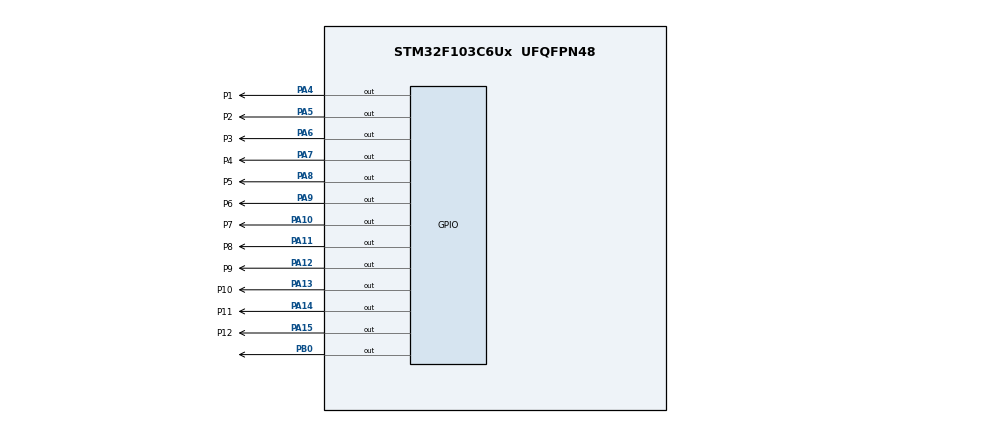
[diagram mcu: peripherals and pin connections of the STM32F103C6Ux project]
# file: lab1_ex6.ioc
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Mcu.Family=STM32F1
Mcu.Name=STM32F103C6Ux
Mcu.Package=UFQFPN48
NVIC.PriorityGroup=NVIC_PRIORITYGROUP_4
PA10.GPIO_Label=P7
PA10.Signal=GPIO_Output
PA11.GPIO_Label=P8
PA11.Signal=GPIO_Output
PA12.GPIO_Label=P9
PA12.Signal=GPIO_Output
PA13.GPIO_Label=P10
PA13.Signal=GPIO_Output
PA14.GPIO_Label=P11
PA14.Signal=GPIO_Output
PA15.GPIO_Label=P12
PA15.Signal=GPIO_Output
PA4.GPIO_Label=P1
PA4.Signal=GPIO_Output
PA5.GPIO_Label=P2
PA5.Signal=GPIO_Output
PA6.GPIO_Label=P3
PA6.Signal=GPIO_Output
PA7.GPIO_Label=P4
PA7.Signal=GPIO_Output
PA8.GPIO_Label=P5
PA8.Signal=GPIO_Output
PA9.GPIO_Label=P6
PA9.Signal=GPIO_Output
PB0.Signal=GPIO_Output
ProjectManager.HeapSize=0x200
ProjectManager.StackSize=0x400
ProjectManager.TargetToolchain=STM32CubeIDE
RCC.APB1Freq_Value=8000000
RCC.APB2Freq_Value=8000000
VP_SYS_VS_ND.Mode=No_Debug
board=custom

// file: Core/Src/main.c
/* USER CODE BEGIN Header */
/**
  ******************************************************************************
  * @file           : main.c
  * @brief          : Main program body
  ******************************************************************************
  * @attention
  *
  * <h2><center>&copy; Copyright (c) 2022 STMicroelectronics.
  * All rights reserved.</center></h2>
  *
  * This software component is licensed by ST under BSD 3-Clause license,
  * the "License"; You may not use this file except in compliance with the
  * License. You may obtain a copy of the License at:
  *                        opensource.org/licenses/BSD-3-Clause
  *
  ******************************************************************************
  */
/* USER CODE END Header */
#include "main.h"

void SystemClock_Config(void);
static void MX_GPIO_Init(void);

int main(void)
{

  /* MCU Configuration--------------------------------------------------------*/

  /* Reset of all peripherals, Initializes the Flash interface and the Systick. */
  HAL_Init();

  /* Configure the system clock */
  SystemClock_Config();

  /* Initialize all configured peripherals */
  MX_GPIO_Init();

  /* Infinite loop */
  /* USER CODE BEGIN WHILE */
  uint8_t i = 1;
  uint8_t j = 6;
  uint8_t k = 3;
  uint8_t h = 0;
  uint8_t t = 0;
   while (1)
   {
    /* USER CODE END WHILE */
	   for(int i = 0; i<12;i++ )
	     {
	   	  setNumonClock(i);
	   	  HAL_Delay(500);
	   	  }
	   ClearAllClock();
   /* USER CODE END 3 */
 }

}
void ClearAllClock(){
  	  HAL_GPIO_WritePin ( P1_GPIO_Port , P1_Pin ,GPIO_PIN_RESET );
  	  HAL_GPIO_WritePin ( P2_GPIO_Port , P2_Pin ,GPIO_PIN_RESET );
  	  HAL_GPIO_WritePin ( P3_GPIO_Port , P3_Pin ,GPIO_PIN_RESET );
  	  HAL_GPIO_WritePin ( P4_GPIO_Port , P4_Pin ,GPIO_PIN_RESET );
  	  HAL_GPIO_WritePin ( P5_GPIO_Port , P5_Pin ,GPIO_PIN_RESET );
  	  HAL_GPIO_WritePin ( P6_GPIO_Port , P6_Pin ,GPIO_PIN_RESET );
  	  HAL_GPIO_WritePin ( P7_GPIO_Port , P7_Pin ,GPIO_PIN_RESET );
  	  HAL_GPIO_WritePin ( P8_GPIO_Port , P8_Pin ,GPIO_PIN_RESET );
  	  HAL_GPIO_WritePin ( P9_GPIO_Port , P9_Pin ,GPIO_PIN_RESET );
  	  HAL_GPIO_WritePin ( P10_GPIO_Port , P10_Pin ,GPIO_PIN_RESET );
  	  HAL_GPIO_WritePin ( P11_GPIO_Port , P11_Pin ,GPIO_PIN_RESET );
  	  HAL_GPIO_WritePin ( P12_GPIO_Port , P12_Pin ,GPIO_PIN_RESET);
}
 void setNumonClock(int a)
   {
	 switch(a){
	 case 0:
 		  	  HAL_GPIO_WritePin ( P12_GPIO_Port , P12_Pin ,GPIO_PIN_SET);
 		  	  break;
	 case 1:

 	  	  HAL_GPIO_WritePin ( P1_GPIO_Port , P1_Pin ,GPIO_PIN_SET );
 	  	  /*HAL_GPIO_WritePin ( P2_GPIO_Port , P2_Pin ,GPIO_PIN_RESET );
 	  	  HAL_GPIO_WritePin ( P3_GPIO_Port , P3_Pin ,GPIO_PIN_RESET);
 	  	  HAL_GPIO_WritePin ( P4_GPIO_Port , P4_Pin ,GPIO_PIN_RESET );
 	  	  HAL_GPIO_WritePin ( P5_GPIO_Port , P5_Pin ,GPIO_PIN_RESET );
 	  	  HAL_GPIO_WritePin ( P6_GPIO_Port , P6_Pin ,GPIO_PIN_RESET );
 	  	  HAL_GPIO_WritePin ( P7_GPIO_Port , P7_Pin ,GPIO_PIN_RESET );
 	  	  HAL_GPIO_WritePin ( P8_GPIO_Port , P8_Pin ,GPIO_PIN_RESET);
 	  	  HAL_GPIO_WritePin ( P9_GPIO_Port , P9_Pin ,GPIO_PIN_RESET );
 	  	  HAL_GPIO_WritePin ( P10_GPIO_Port , P10_Pin ,GPIO_PIN_RESET );
 	  	  HAL_GPIO_WritePin ( P11_GPIO_Port , P11_Pin ,GPIO_PIN_RESET );
 	  	  HAL_GPIO_WritePin ( P12_GPIO_Port , P12_Pin ,GPIO_PIN_RESET );*/

 	break;
	 case 2:

 	  	  //HAL_GPIO_WritePin ( P1_GPIO_Port , P1_Pin ,GPIO_PIN_RESET );
 	  	  HAL_GPIO_WritePin ( P2_GPIO_Port , P2_Pin ,GPIO_PIN_SET );
 	  	  /*HAL_GPIO_WritePin ( P3_GPIO_Port , P3_Pin ,GPIO_PIN_RESET );
 	  	  HAL_GPIO_WritePin ( P4_GPIO_Port , P4_Pin ,GPIO_PIN_RESET );
 	  	  HAL_GPIO_WritePin ( P5_GPIO_Port , P5_Pin ,GPIO_PIN_RESET );
 	  	  HAL_GPIO_WritePin ( P6_GPIO_Port , P6_Pin ,GPIO_PIN_RESET);
 	  	  HAL_GPIO_WritePin ( P7_GPIO_Port , P7_Pin ,GPIO_PIN_RESET );
 	  	  HAL_GPIO_WritePin ( P8_GPIO_Port , P8_Pin ,GPIO_PIN_RESET );
 	  	  HAL_GPIO_WritePin ( P9_GPIO_Port , P9_Pin ,GPIO_PIN_RESET);
 	  	  HAL_GPIO_WritePin ( P10_GPIO_Port , P10_Pin ,GPIO_PIN_RESET );
 	  	  HAL_GPIO_WritePin ( P11_GPIO_Port , P11_Pin ,GPIO_PIN_RESET );
 	  	  HAL_GPIO_WritePin ( P12_GPIO_Port , P12_Pin ,GPIO_PIN_RESET );*/

 	break;
	 case 3:

 	  	  //HAL_GPIO_WritePin ( P1_GPIO_Port , P1_Pin ,GPIO_PIN_RESET );
 	  	  //HAL_GPIO_WritePin ( P2_GPIO_Port , P2_Pin ,GPIO_PIN_RESET );
 	  	  HAL_GPIO_WritePin ( P3_GPIO_Port , P3_Pin ,GPIO_PIN_SET );
 	  	  /*HAL_GPIO_WritePin ( P4_GPIO_Port , P4_Pin ,GPIO_PIN_RESET );
 	  	  HAL_GPIO_WritePin ( P5_GPIO_Port , P5_Pin ,GPIO_PIN_RESET );
 	  	  HAL_GPIO_WritePin ( P6_GPIO_Port , P6_Pin ,GPIO_PIN_RESET );
 	  	  HAL_GPIO_WritePin ( P7_GPIO_Port , P7_Pin ,GPIO_PIN_RESET );
 	  	  HAL_GPIO_WritePin ( P8_GPIO_Port , P8_Pin ,GPIO_PIN_RESET );
 	  	  HAL_GPIO_WritePin ( P9_GPIO_Port , P9_Pin ,GPIO_PIN_RESET );
 	  	  HAL_GPIO_WritePin ( P10_GPIO_Port , P10_Pin ,GPIO_PIN_RESET );
 	  	  HAL_GPIO_WritePin ( P11_GPIO_Port , P11_Pin ,GPIO_PIN_RESET );
 	  	  HAL_GPIO_WritePin ( P12_GPIO_Port , P12_Pin ,GPIO_PIN_RESET);*/

 	break;
	 case 4:

 	  	 /*HAL_GPIO_WritePin ( P1_GPIO_Port , P1_Pin ,GPIO_PIN_RESET );
 	  	 HAL_GPIO_WritePin ( P2_GPIO_Port , P2_Pin ,GPIO_PIN_RESET );
 	  	 HAL_GPIO_WritePin ( P3_GPIO_Port , P3_Pin ,GPIO_PIN_RESET );*/
 		 HAL_GPIO_WritePin ( P4_GPIO_Port , P4_Pin ,GPIO_PIN_SET );
 	  	 /*HAL_GPIO_WritePin ( P5_GPIO_Port , P5_Pin ,GPIO_PIN_RESET );
 	  	 HAL_GPIO_WritePin ( P6_GPIO_Port , P6_Pin ,GPIO_PIN_RESET );
 	  	 HAL_GPIO_WritePin ( P7_GPIO_Port , P7_Pin ,GPIO_PIN_RESET );
 	  	 HAL_GPIO_WritePin ( P8_GPIO_Port , P8_Pin ,GPIO_PIN_RESET );
 	  	 HAL_GPIO_WritePin ( P9_GPIO_Port , P9_Pin ,GPIO_PIN_RESET );
 	  	 HAL_GPIO_WritePin ( P10_GPIO_Port , P10_Pin ,GPIO_PIN_RESET );
 	  	 HAL_GPIO_WritePin ( P11_GPIO_Port , P11_Pin ,GPIO_PIN_RESET );
 	  	 HAL_GPIO_WritePin ( P12_GPIO_Port , P12_Pin ,GPIO_PIN_RESET);*/

 	break;
	 case 5:

 	  	  //HAL_GPIO_WritePin ( P1_GPIO_Port , P1_Pin ,GPIO_PIN_RESET );
 	  	  //HAL_GPIO_WritePin ( P2_GPIO_Port , P2_Pin ,GPIO_PIN_RESET );
 	  	  //HAL_GPIO_WritePin ( P3_GPIO_Port , P3_Pin ,GPIO_PIN_RESET );
 	  	  //HAL_GPIO_WritePin ( P4_GPIO_Port , P4_Pin ,GPIO_PIN_RESET );
 	  	   HAL_GPIO_WritePin ( P5_GPIO_Port , P5_Pin ,GPIO_PIN_SET );
 	  	  //HAL_GPIO_WritePin ( P6_GPIO_Port , P6_Pin ,GPIO_PIN_RESET );
 	  	  //HAL_GPIO_WritePin ( P7_GPIO_Port , P7_Pin ,GPIO_PIN_RESET );
 	  	  //HAL_GPIO_WritePin ( P8_GPIO_Port , P8_Pin ,GPIO_PIN_RESET );
 	  	  //HAL_GPIO_WritePin ( P9_GPIO_Port , P9_Pin ,GPIO_PIN_RESET );
 	  	  //HAL_GPIO_WritePin ( P10_GPIO_Port , P10_Pin ,GPIO_PIN_RESET );
 	  	  //HAL_GPIO_WritePin ( P11_GPIO_Port , P11_Pin ,GPIO_PIN_RESET );
 	  	  //HAL_GPIO_WritePin ( P12_GPIO_Port , P12_Pin ,GPIO_PIN_RESET);

 	break;
	 case 6:

 	  	  //HAL_GPIO_WritePin ( P1_GPIO_Port , P1_Pin ,GPIO_PIN_RESET );
 	  	  //HAL_GPIO_WritePin ( P2_GPIO_Port , P2_Pin ,GPIO_PIN_RESET );
 	  	  //HAL_GPIO_WritePin ( P3_GPIO_Port , P3_Pin ,GPIO_PIN_RESET );
 	  	  //HAL_GPIO_WritePin ( P4_GPIO_Port , P4_Pin ,GPIO_PIN_RESET );
 	  	  //HAL_GPIO_WritePin ( P5_GPIO_Port , P5_Pin ,GPIO_PIN_RESET );
 	  	  HAL_GPIO_WritePin ( P6_GPIO_Port , P6_Pin ,GPIO_PIN_SET );
 	  	  //HAL_GPIO_WritePin ( P7_GPIO_Port , P7_Pin ,GPIO_PIN_RESET );
 	  	  //HAL_GPIO_WritePin ( P8_GPIO_Port , P8_Pin ,GPIO_PIN_RESET );
 	  	  //HAL_GPIO_WritePin ( P9_GPIO_Port , P9_Pin ,GPIO_PIN_RESET );
 	  	  //HAL_GPIO_WritePin ( P10_GPIO_Port , P10_Pin ,GPIO_PIN_RESET );
 	  	  //HAL_GPIO_WritePin ( P11_GPIO_Port , P11_Pin ,GPIO_PIN_RESET );
 	  	  //HAL_GPIO_WritePin ( P12_GPIO_Port , P12_Pin ,GPIO_PIN_RESET);

 	break;
	 case 7:

 	  	  //HAL_GPIO_WritePin ( P1_GPIO_Port , P1_Pin ,GPIO_PIN_RESET );
 	  	  //HAL_GPIO_WritePin ( P2_GPIO_Port , P2_Pin ,GPIO_PIN_RESET );
 	  	  //HAL_GPIO_WritePin ( P3_GPIO_Port , P3_Pin ,GPIO_PIN_RESET );
 	  	  //HAL_GPIO_WritePin ( P4_GPIO_Port , P4_Pin ,GPIO_PIN_RESET );
 	  	  //HAL_GPIO_WritePin ( P5_GPIO_Port , P5_Pin ,GPIO_PIN_RESET );
 	  	 // HAL_GPIO_WritePin ( P6_GPIO_Port , P6_Pin ,GPIO_PIN_RESET );
 	  	  HAL_GPIO_WritePin ( P7_GPIO_Port , P7_Pin ,GPIO_PIN_SET );
 	  	 // HAL_GPIO_WritePin ( P8_GPIO_Port , P8_Pin ,GPIO_PIN_RESET );
 	  	 // HAL_GPIO_WritePin ( P9_GPIO_Port , P9_Pin ,GPIO_PIN_RESET );
 	  	//  HAL_GPIO_WritePin ( P10_GPIO_Port , P10_Pin ,GPIO_PIN_RESET );
 	  	//  HAL_GPIO_WritePin ( P11_GPIO_Port , P11_Pin ,GPIO_PIN_RESET );
 	  	//  HAL_GPIO_WritePin ( P12_GPIO_Port , P12_Pin ,GPIO_PIN_RESET);

 	break;
	 case 8:

 	 	  //HAL_GPIO_WritePin ( P1_GPIO_Port , P1_Pin ,GPIO_PIN_RESET );
 	  	  //HAL_GPIO_WritePin ( P2_GPIO_Port , P2_Pin ,GPIO_PIN_RESET );
 	  	  //HAL_GPIO_WritePin ( P3_GPIO_Port , P3_Pin ,GPIO_PIN_RESET );
 	  	  //HAL_GPIO_WritePin ( P4_GPIO_Port , P4_Pin ,GPIO_PIN_RESET );
 	  	  //HAL_GPIO_WritePin ( P5_GPIO_Port , P5_Pin ,GPIO_PIN_RESET );
 	  	  //HAL_GPIO_WritePin ( P6_GPIO_Port , P6_Pin ,GPIO_PIN_RESET );
 	  	  //HAL_GPIO_WritePin ( P7_GPIO_Port , P7_Pin ,GPIO_PIN_RESET );
 	  	  HAL_GPIO_WritePin ( P8_GPIO_Port , P8_Pin ,GPIO_PIN_SET );
 	  	  //HAL_GPIO_WritePin ( P9_GPIO_Port , P9_Pin ,GPIO_PIN_RESET );
 	  	  //HAL_GPIO_WritePin ( P10_GPIO_Port , P10_Pin ,GPIO_PIN_RESET );
 	  	  //HAL_GPIO_WritePin ( P11_GPIO_Port , P11_Pin ,GPIO_PIN_RESET );
 	  	  //HAL_GPIO_WritePin ( P12_GPIO_Port , P12_Pin ,GPIO_PIN_RESET);

 	break;
	 case 9:

 	  	  //HAL_GPIO_WritePin ( P1_GPIO_Port , P1_Pin ,GPIO_PIN_RESET );
 	  	  //HAL_GPIO_WritePin ( P2_GPIO_Port , P2_Pin ,GPIO_PIN_RESET );
 	  	  //HAL_GPIO_WritePin ( P3_GPIO_Port , P3_Pin ,GPIO_PIN_RESET );
 	  	  //HAL_GPIO_WritePin ( P4_GPIO_Port , P4_Pin ,GPIO_PIN_RESET );
 	  	  //HAL_GPIO_WritePin ( P5_GPIO_Port , P5_Pin ,GPIO_PIN_RESET );
 	  	  //HAL_GPIO_WritePin ( P6_GPIO_Port , P6_Pin ,GPIO_PIN_RESET );
 	  	  //HAL_GPIO_WritePin ( P7_GPIO_Port , P7_Pin ,GPIO_PIN_RESET );
 	  	  //HAL_GPIO_WritePin ( P8_GPIO_Port , P8_Pin ,GPIO_PIN_RESET );
 	  	  HAL_GPIO_WritePin ( P9_GPIO_Port , P9_Pin ,GPIO_PIN_SET );
 	  	  //HAL_GPIO_WritePin ( P10_GPIO_Port , P10_Pin ,GPIO_PIN_RESET );
 	  	  //HAL_GPIO_WritePin ( P11_GPIO_Port , P11_Pin ,GPIO_PIN_RESET );
 	  	  //HAL_GPIO_WritePin ( P12_GPIO_Port , P12_Pin ,GPIO_PIN_RESET);

 	break;
	 case 10:

 	  	  //HAL_GPIO_WritePin ( P1_GPIO_Port , P1_Pin ,GPIO_PIN_RESET );
 	  	  //HAL_GPIO_WritePin ( P2_GPIO_Port , P2_Pin ,GPIO_PIN_RESET );
 	  	  //HAL_GPIO_WritePin ( P3_GPIO_Port , P3_Pin ,GPIO_PIN_RESET );
 	  	  //HAL_GPIO_WritePin ( P4_GPIO_Port , P4_Pin ,GPIO_PIN_RESET );
 	  	  //HAL_GPIO_WritePin ( P5_GPIO_Port , P5_Pin ,GPIO_PIN_RESET );
 	  	  //HAL_GPIO_WritePin ( P6_GPIO_Port , P6_Pin ,GPIO_PIN_RESET );
 	  	  //HAL_GPIO_WritePin ( P7_GPIO_Port , P7_Pin ,GPIO_PIN_RESET );
 	  	  //HAL_GPIO_WritePin ( P8_GPIO_Port , P8_Pin ,GPIO_PIN_RESET );
 	  	  //HAL_GPIO_WritePin ( P9_GPIO_Port , P9_Pin ,GPIO_PIN_RESET );
 	  	  HAL_GPIO_WritePin ( P10_GPIO_Port , P10_Pin ,GPIO_PIN_SET );
 	  	  //HAL_GPIO_WritePin ( P11_GPIO_Port , P11_Pin ,GPIO_PIN_RESET );
 	  	  //HAL_GPIO_WritePin ( P12_GPIO_Port , P12_Pin ,GPIO_PIN_RESET);

 		break;
	 case 11:

 	  	  //HAL_GPIO_WritePin ( P1_GPIO_Port , P1_Pin ,GPIO_PIN_RESET );
 	  	  //HAL_GPIO_WritePin ( P2_GPIO_Port , P2_Pin ,GPIO_PIN_RESET );
 	  	  //HAL_GPIO_WritePin ( P3_GPIO_Port , P3_Pin ,GPIO_PIN_RESET );
 	  	  //HAL_GPIO_WritePin ( P4_GPIO_Port , P4_Pin ,GPIO_PIN_RESET );
 	  	  //HAL_GPIO_WritePin ( P5_GPIO_Port , P5_Pin ,GPIO_PIN_RESET );
 	  	  //HAL_GPIO_WritePin ( P6_GPIO_Port , P6_Pin ,GPIO_PIN_RESET );
 	  	  //HAL_GPIO_WritePin ( P7_GPIO_Port , P7_Pin ,GPIO_PIN_RESET );
 	  	  //HAL_GPIO_WritePin ( P8_GPIO_Port , P8_Pin ,GPIO_PIN_RESET );
 	  	  //HAL_GPIO_WritePin ( P9_GPIO_Port , P9_Pin ,GPIO_PIN_RESET );
 	  	  //HAL_GPIO_WritePin ( P10_GPIO_Port , P10_Pin ,GPIO_PIN_RESET );
 	  	  HAL_GPIO_WritePin ( P11_GPIO_Port , P11_Pin ,GPIO_PIN_SET );
 	  	  //HAL_GPIO_WritePin ( P12_GPIO_Port , P12_Pin ,GPIO_PIN_RESET);

 		break;
	 default:
		 break;
	 }
   }
 void setNumoffClock(int a)
    {
  	/*if(a==0)
  	{
  		  	  HAL_GPIO_WritePin ( P1_GPIO_Port , P1_Pin ,GPIO_PIN_RESET );
  		  	  HAL_GPIO_WritePin ( P2_GPIO_Port , P2_Pin ,GPIO_PIN_RESET );
  		  	  HAL_GPIO_WritePin ( P3_GPIO_Port , P3_Pin ,GPIO_PIN_RESET );
  		  	  HAL_GPIO_WritePin ( P4_GPIO_Port , P4_Pin ,GPIO_PIN_RESET );
  		  	  HAL_GPIO_WritePin ( P5_GPIO_Port , P5_Pin ,GPIO_PIN_RESET );
  		  	  HAL_GPIO_WritePin ( P6_GPIO_Port , P6_Pin ,GPIO_PIN_RESET );
  		  	  HAL_GPIO_WritePin ( P7_GPIO_Port , P7_Pin ,GPIO_PIN_RESET );
  		  	  HAL_GPIO_WritePin ( P8_GPIO_Port , P8_Pin ,GPIO_PIN_RESET );
  		  	  HAL_GPIO_WritePin ( P9_GPIO_Port , P9_Pin ,GPIO_PIN_RESET );
  		  	  HAL_GPIO_WritePin ( P10_GPIO_Port , P10_Pin ,GPIO_PIN_RESET );
  		  	  HAL_GPIO_WritePin ( P11_GPIO_Port , P11_Pin ,GPIO_PIN_RESET );
  		  	  HAL_GPIO_WritePin ( P12_GPIO_Port , P12_Pin ,GPIO_PIN_RESET);
  	}*/
	 switch(a){
	 case 0:
 		  	  HAL_GPIO_WritePin ( P12_GPIO_Port , P12_Pin ,GPIO_PIN_RESET);
 		  	  break;
	 case 1:

 	  	  HAL_GPIO_WritePin ( P1_GPIO_Port , P1_Pin ,GPIO_PIN_RESET );
 	  	  /*HAL_GPIO_WritePin ( P2_GPIO_Port , P2_Pin ,GPIO_PIN_RESET );
 	  	  HAL_GPIO_WritePin ( P3_GPIO_Port , P3_Pin ,GPIO_PIN_RESET);
 	  	  HAL_GPIO_WritePin ( P4_GPIO_Port , P4_Pin ,GPIO_PIN_RESET );
 	  	  HAL_GPIO_WritePin ( P5_GPIO_Port , P5_Pin ,GPIO_PIN_RESET );
 	  	  HAL_GPIO_WritePin ( P6_GPIO_Port , P6_Pin ,GPIO_PIN_RESET );
 	  	  HAL_GPIO_WritePin ( P7_GPIO_Port , P7_Pin ,GPIO_PIN_RESET );
 	  	  HAL_GPIO_WritePin ( P8_GPIO_Port , P8_Pin ,GPIO_PIN_RESET);
 	  	  HAL_GPIO_WritePin ( P9_GPIO_Port , P9_Pin ,GPIO_PIN_RESET );
 	  	  HAL_GPIO_WritePin ( P10_GPIO_Port , P10_Pin ,GPIO_PIN_RESET );
 	  	  HAL_GPIO_WritePin ( P11_GPIO_Port , P11_Pin ,GPIO_PIN_RESET );
 	  	  HAL_GPIO_WritePin ( P12_GPIO_Port , P12_Pin ,GPIO_PIN_RESET );*/

 	break;
	 case 2:

 	  	  //HAL_GPIO_WritePin ( P1_GPIO_Port , P1_Pin ,GPIO_PIN_RESET );
 	  	  HAL_GPIO_WritePin ( P2_GPIO_Port , P2_Pin ,GPIO_PIN_RESET );
 	  	  /*HAL_GPIO_WritePin ( P3_GPIO_Port , P3_Pin ,GPIO_PIN_RESET );
 	  	  HAL_GPIO_WritePin ( P4_GPIO_Port , P4_Pin ,GPIO_PIN_RESET );
 	  	  HAL_GPIO_WritePin ( P5_GPIO_Port , P5_Pin ,GPIO_PIN_RESET );
 	  	  HAL_GPIO_WritePin ( P6_GPIO_Port , P6_Pin ,GPIO_PIN_RESET);
 	  	  HAL_GPIO_WritePin ( P7_GPIO_Port , P7_Pin ,GPIO_PIN_RESET );
 	  	  HAL_GPIO_WritePin ( P8_GPIO_Port , P8_Pin ,GPIO_PIN_RESET );
 	  	  HAL_GPIO_WritePin ( P9_GPIO_Port , P9_Pin ,GPIO_PIN_RESET);
 	  	  HAL_GPIO_WritePin ( P10_GPIO_Port , P10_Pin ,GPIO_PIN_RESET );
 	  	  HAL_GPIO_WritePin ( P11_GPIO_Port , P11_Pin ,GPIO_PIN_RESET );
 	  	  HAL_GPIO_WritePin ( P12_GPIO_Port , P12_Pin ,GPIO_PIN_RESET );*/

 	break;
	 case 3:

 	  	  //HAL_GPIO_WritePin ( P1_GPIO_Port , P1_Pin ,GPIO_PIN_RESET );
 	  	  //HAL_GPIO_WritePin ( P2_GPIO_Port , P2_Pin ,GPIO_PIN_RESET );
 	  	  HAL_GPIO_WritePin ( P3_GPIO_Port , P3_Pin ,GPIO_PIN_RESET );
 	  	  /*HAL_GPIO_WritePin ( P4_GPIO_Port , P4_Pin ,GPIO_PIN_RESET );
 	  	  HAL_GPIO_WritePin ( P5_GPIO_Port , P5_Pin ,GPIO_PIN_RESET );
 	  	  HAL_GPIO_WritePin ( P6_GPIO_Port , P6_Pin ,GPIO_PIN_RESET );
 	  	  HAL_GPIO_WritePin ( P7_GPIO_Port , P7_Pin ,GPIO_PIN_RESET );
 	  	  HAL_GPIO_WritePin ( P8_GPIO_Port , P8_Pin ,GPIO_PIN_RESET );
 	  	  HAL_GPIO_WritePin ( P9_GPIO_Port , P9_Pin ,GPIO_PIN_RESET );
 	  	  HAL_GPIO_WritePin ( P10_GPIO_Port , P10_Pin ,GPIO_PIN_RESET );
 	  	  HAL_GPIO_WritePin ( P11_GPIO_Port , P11_Pin ,GPIO_PIN_RESET );
 	  	  HAL_GPIO_WritePin ( P12_GPIO_Port , P12_Pin ,GPIO_PIN_RESET);*/

 	break;
	 case 4:

 	  	 /*HAL_GPIO_WritePin ( P1_GPIO_Port , P1_Pin ,GPIO_PIN_RESET );
 	  	 HAL_GPIO_WritePin ( P2_GPIO_Port , P2_Pin ,GPIO_PIN_RESET );
 	  	 HAL_GPIO_WritePin ( P3_GPIO_Port , P3_Pin ,GPIO_PIN_RESET );*/
 		 HAL_GPIO_WritePin ( P4_GPIO_Port , P4_Pin ,GPIO_PIN_RESET );
 	  	 /*HAL_GPIO_WritePin ( P5_GPIO_Port , P5_Pin ,GPIO_PIN_RESET );
 	  	 HAL_GPIO_WritePin ( P6_GPIO_Port , P6_Pin ,GPIO_PIN_RESET );
 	  	 HAL_GPIO_WritePin ( P7_GPIO_Port , P7_Pin ,GPIO_PIN_RESET );
 	  	 HAL_GPIO_WritePin ( P8_GPIO_Port , P8_Pin ,GPIO_PIN_RESET );
 	  	 HAL_GPIO_WritePin ( P9_GPIO_Port , P9_Pin ,GPIO_PIN_RESET );
 	  	 HAL_GPIO_WritePin ( P10_GPIO_Port , P10_Pin ,GPIO_PIN_RESET );
 	  	 HAL_GPIO_WritePin ( P11_GPIO_Port , P11_Pin ,GPIO_PIN_RESET );
 	  	 HAL_GPIO_WritePin ( P12_GPIO_Port , P12_Pin ,GPIO_PIN_RESET);*/

 	break;
	 case 5:

 	  	  //HAL_GPIO_WritePin ( P1_GPIO_Port , P1_Pin ,GPIO_PIN_RESET );
 	  	  //HAL_GPIO_WritePin ( P2_GPIO_Port , P2_Pin ,GPIO_PIN_RESET );
 	  	  //HAL_GPIO_WritePin ( P3_GPIO_Port , P3_Pin ,GPIO_PIN_RESET );
 	  	  //HAL_GPIO_WritePin ( P4_GPIO_Port , P4_Pin ,GPIO_PIN_RESET );
 	  	   HAL_GPIO_WritePin ( P5_GPIO_Port , P5_Pin ,GPIO_PIN_RESET );
 	  	  //HAL_GPIO_WritePin ( P6_GPIO_Port , P6_Pin ,GPIO_PIN_RESET );
 	  	  //HAL_GPIO_WritePin ( P7_GPIO_Port , P7_Pin ,GPIO_PIN_RESET );
 	  	  //HAL_GPIO_WritePin ( P8_GPIO_Port , P8_Pin ,GPIO_PIN_RESET );
 	  	  //HAL_GPIO_WritePin ( P9_GPIO_Port , P9_Pin ,GPIO_PIN_RESET );
 	  	  //HAL_GPIO_WritePin ( P10_GPIO_Port , P10_Pin ,GPIO_PIN_RESET );
 	  	  //HAL_GPIO_WritePin ( P11_GPIO_Port , P11_Pin ,GPIO_PIN_RESET );
 	  	  //HAL_GPIO_WritePin ( P12_GPIO_Port , P12_Pin ,GPIO_PIN_RESET);

 	break;
	 case 6:

 	  	  //HAL_GPIO_WritePin ( P1_GPIO_Port , P1_Pin ,GPIO_PIN_RESET );
 	  	  //HAL_GPIO_WritePin ( P2_GPIO_Port , P2_Pin ,GPIO_PIN_RESET );
 	  	  //HAL_GPIO_WritePin ( P3_GPIO_Port , P3_Pin ,GPIO_PIN_RESET );
 	  	  //HAL_GPIO_WritePin ( P4_GPIO_Port , P4_Pin ,GPIO_PIN_RESET );
 	  	  //HAL_GPIO_WritePin ( P5_GPIO_Port , P5_Pin ,GPIO_PIN_RESET );
 	  	  HAL_GPIO_WritePin ( P6_GPIO_Port , P6_Pin ,GPIO_PIN_RESET );
 	  	  //HAL_GPIO_WritePin ( P7_GPIO_Port , P7_Pin ,GPIO_PIN_RESET );
 	  	  //HAL_GPIO_WritePin ( P8_GPIO_Port , P8_Pin ,GPIO_PIN_RESET );
 	  	  //HAL_GPIO_WritePin ( P9_GPIO_Port , P9_Pin ,GPIO_PIN_RESET );
 	  	  //HAL_GPIO_WritePin ( P10_GPIO_Port , P10_Pin ,GPIO_PIN_RESET );
 	  	  //HAL_GPIO_WritePin ( P11_GPIO_Port , P11_Pin ,GPIO_PIN_RESET );
 	  	  //HAL_GPIO_WritePin ( P12_GPIO_Port , P12_Pin ,GPIO_PIN_RESET);

 	break;
	 case 7:

 	  	  //HAL_GPIO_WritePin ( P1_GPIO_Port , P1_Pin ,GPIO_PIN_RESET );
 	  	  //HAL_GPIO_WritePin ( P2_GPIO_Port , P2_Pin ,GPIO_PIN_RESET );
 	  	  //HAL_GPIO_WritePin ( P3_GPIO_Port , P3_Pin ,GPIO_PIN_RESET );
 	  	  //HAL_GPIO_WritePin ( P4_GPIO_Port , P4_Pin ,GPIO_PIN_RESET );
 	  	  //HAL_GPIO_WritePin ( P5_GPIO_Port , P5_Pin ,GPIO_PIN_RESET );
 	  	 // HAL_GPIO_WritePin ( P6_GPIO_Port , P6_Pin ,GPIO_PIN_RESET );
 	  	  HAL_GPIO_WritePin ( P7_GPIO_Port , P7_Pin ,GPIO_PIN_RESET );
 	  	 // HAL_GPIO_WritePin ( P8_GPIO_Port , P8_Pin ,GPIO_PIN_RESET );
 	  	 // HAL_GPIO_WritePin ( P9_GPIO_Port , P9_Pin ,GPIO_PIN_RESET );
 	  	//  HAL_GPIO_WritePin ( P10_GPIO_Port , P10_Pin ,GPIO_PIN_RESET );
 	  	//  HAL_GPIO_WritePin ( P11_GPIO_Port , P11_Pin ,GPIO_PIN_RESET );
 	  	//  HAL_GPIO_WritePin ( P12_GPIO_Port , P12_Pin ,GPIO_PIN_RESET);

 	break;
	 case 8:

 	  	  //HAL_GPIO_WritePin ( P1_GPIO_Port , P1_Pin ,GPIO_PIN_RESET );
 	  	  //HAL_GPIO_WritePin ( P2_GPIO_Port , P2_Pin ,GPIO_PIN_RESET );
 	  	  //HAL_GPIO_WritePin ( P3_GPIO_Port , P3_Pin ,GPIO_PIN_RESET );
 	  	  //HAL_GPIO_WritePin ( P4_GPIO_Port , P4_Pin ,GPIO_PIN_RESET );
 	  	  //HAL_GPIO_WritePin ( P5_GPIO_Port , P5_Pin ,GPIO_PIN_RESET );
 	  	  //HAL_GPIO_WritePin ( P6_GPIO_Port , P6_Pin ,GPIO_PIN_RESET );
 	  	  //HAL_GPIO_WritePin ( P7_GPIO_Port , P7_Pin ,GPIO_PIN_RESET );
 	  	  HAL_GPIO_WritePin ( P8_GPIO_Port , P8_Pin ,GPIO_PIN_RESET );
 	  	  //HAL_GPIO_WritePin ( P9_GPIO_Port , P9_Pin ,GPIO_PIN_RESET );
 	  	  //HAL_GPIO_WritePin ( P10_GPIO_Port , P10_Pin ,GPIO_PIN_RESET );
 	  	  //HAL_GPIO_WritePin ( P11_GPIO_Port , P11_Pin ,GPIO_PIN_RESET );
 	  	  //HAL_GPIO_WritePin ( P12_GPIO_Port , P12_Pin ,GPIO_PIN_RESET);

 	break;
	 case 9:

 	  	  //HAL_GPIO_WritePin ( P1_GPIO_Port , P1_Pin ,GPIO_PIN_RESET );
 	  	  //HAL_GPIO_WritePin ( P2_GPIO_Port , P2_Pin ,GPIO_PIN_RESET );
 	  	  //HAL_GPIO_WritePin ( P3_GPIO_Port , P3_Pin ,GPIO_PIN_RESET );
 	  	  //HAL_GPIO_WritePin ( P4_GPIO_Port , P4_Pin ,GPIO_PIN_RESET );
 	  	  //HAL_GPIO_WritePin ( P5_GPIO_Port , P5_Pin ,GPIO_PIN_RESET );
 	  	  //HAL_GPIO_WritePin ( P6_GPIO_Port , P6_Pin ,GPIO_PIN_RESET );
 	  	  //HAL_GPIO_WritePin ( P7_GPIO_Port , P7_Pin ,GPIO_PIN_RESET );
 	  	  //HAL_GPIO_WritePin ( P8_GPIO_Port , P8_Pin ,GPIO_PIN_RESET );
 	  	  HAL_GPIO_WritePin ( P9_GPIO_Port , P9_Pin ,GPIO_PIN_RESET );
 	  	  //HAL_GPIO_WritePin ( P10_GPIO_Port , P10_Pin ,GPIO_PIN_RESET );
 	  	  //HAL_GPIO_WritePin ( P11_GPIO_Port , P11_Pin ,GPIO_PIN_RESET );
 	  	  //HAL_GPIO_WritePin ( P12_GPIO_Port , P12_Pin ,GPIO_PIN_RESET);

 	break;
	 case 10:

 	  	  //HAL_GPIO_WritePin ( P1_GPIO_Port , P1_Pin ,GPIO_PIN_RESET );
 	  	  //HAL_GPIO_WritePin ( P2_GPIO_Port , P2_Pin ,GPIO_PIN_RESET );
 	  	  //HAL_GPIO_WritePin ( P3_GPIO_Port , P3_Pin ,GPIO_PIN_RESET );
 	  	  //HAL_GPIO_WritePin ( P4_GPIO_Port , P4_Pin ,GPIO_PIN_RESET );
 	  	  //HAL_GPIO_WritePin ( P5_GPIO_Port , P5_Pin ,GPIO_PIN_RESET );
 	  	  //HAL_GPIO_WritePin ( P6_GPIO_Port , P6_Pin ,GPIO_PIN_RESET );
 	  	  //HAL_GPIO_WritePin ( P7_GPIO_Port , P7_Pin ,GPIO_PIN_RESET );
 	  	  //HAL_GPIO_WritePin ( P8_GPIO_Port , P8_Pin ,GPIO_PIN_RESET );
 	  	  //HAL_GPIO_WritePin ( P9_GPIO_Port , P9_Pin ,GPIO_PIN_RESET );
 	  	  HAL_GPIO_WritePin ( P10_GPIO_Port , P10_Pin ,GPIO_PIN_RESET );
 	  	  //HAL_GPIO_WritePin ( P11_GPIO_Port , P11_Pin ,GPIO_PIN_RESET );
 	  	  //HAL_GPIO_WritePin ( P12_GPIO_Port , P12_Pin ,GPIO_PIN_RESET);

 		break;
	 case 11:

 	  	  //HAL_GPIO_WritePin ( P1_GPIO_Port , P1_Pin ,GPIO_PIN_RESET );
 	  	  //HAL_GPIO_WritePin ( P2_GPIO_Port , P2_Pin ,GPIO_PIN_RESET );
 	  	  //HAL_GPIO_WritePin ( P3_GPIO_Port , P3_Pin ,GPIO_PIN_RESET );
 	  	  //HAL_GPIO_WritePin ( P4_GPIO_Port , P4_Pin ,GPIO_PIN_RESET );
 	  	  //HAL_GPIO_WritePin ( P5_GPIO_Port , P5_Pin ,GPIO_PIN_RESET );
 	  	  //HAL_GPIO_WritePin ( P6_GPIO_Port , P6_Pin ,GPIO_PIN_RESET );
 	  	  //HAL_GPIO_WritePin ( P7_GPIO_Port , P7_Pin ,GPIO_PIN_RESET );
 	  	  //HAL_GPIO_WritePin ( P8_GPIO_Port , P8_Pin ,GPIO_PIN_RESET );
 	  	  //HAL_GPIO_WritePin ( P9_GPIO_Port , P9_Pin ,GPIO_PIN_RESET );
 	  	  //HAL_GPIO_WritePin ( P10_GPIO_Port , P10_Pin ,GPIO_PIN_RESET );
 	  	  HAL_GPIO_WritePin ( P11_GPIO_Port , P11_Pin ,GPIO_PIN_RESET );
 	  	  //HAL_GPIO_WritePin ( P12_GPIO_Port , P12_Pin ,GPIO_PIN_RESET);

 		break;
	 default:
		 break;
	}
 }

void SystemClock_Config(void)
{
  RCC_OscInitTypeDef RCC_OscInitStruct = {0};
  RCC_ClkInitTypeDef RCC_ClkInitStruct = {0};

  /** Initializes the RCC Oscillators according to the specified parameters
  * in the RCC_OscInitTypeDef structure.
  */
  RCC_OscInitStruct.OscillatorType = RCC_OSCILLATORTYPE_HSI;
  RCC_OscInitStruct.HSIState = RCC_HSI_ON;
  RCC_OscInitStruct.HSICalibrationValue = RCC_HSICALIBRATION_DEFAULT;
  RCC_OscInitStruct.PLL.PLLState = RCC_PLL_NONE;
  if (HAL_RCC_OscConfig(&RCC_OscInitStruct) != HAL_OK)
  {
    Error_Handler();
  }
  /** Initializes the CPU, AHB and APB buses clocks
  */
  RCC_ClkInitStruct.ClockType = RCC_CLOCKTYPE_HCLK|RCC_CLOCKTYPE_SYSCLK
                              |RCC_CLOCKTYPE_PCLK1|RCC_CLOCKTYPE_PCLK2;
  RCC_ClkInitStruct.SYSCLKSource = RCC_SYSCLKSOURCE_HSI;
  RCC_ClkInitStruct.AHBCLKDivider = RCC_SYSCLK_DIV1;
  RCC_ClkInitStruct.APB1CLKDivider = RCC_HCLK_DIV1;
  RCC_ClkInitStruct.APB2CLKDivider = RCC_HCLK_DIV1;

  if (HAL_RCC_ClockConfig(&RCC_ClkInitStruct, FLASH_LATENCY_0) != HAL_OK)
  {
    Error_Handler();
  }
}

static void MX_GPIO_Init(void)
{
  GPIO_InitTypeDef GPIO_InitStruct = {0};

  /* GPIO Ports Clock Enable */
  __HAL_RCC_GPIOA_CLK_ENABLE();
  __HAL_RCC_GPIOB_CLK_ENABLE();

  /*Configure GPIO pin Output Level */
  HAL_GPIO_WritePin(GPIOA, P1_Pin|P2_Pin|P3_Pin|P4_Pin
                          |P5_Pin|P6_Pin|P7_Pin|P8_Pin
                          |P9_Pin|P10_Pin|P11_Pin|P12_Pin, GPIO_PIN_RESET);

  /*Configure GPIO pin Output Level */
  HAL_GPIO_WritePin(GPIOB, GPIO_PIN_0, GPIO_PIN_RESET);

  /*Configure GPIO pins : P1_Pin P2_Pin P3_Pin P4_Pin
                           P5_Pin P6_Pin P7_Pin P8_Pin
                           P9_Pin P10_Pin P11_Pin P12_Pin */
  GPIO_InitStruct.Pin = P1_Pin|P2_Pin|P3_Pin|P4_Pin
                          |P5_Pin|P6_Pin|P7_Pin|P8_Pin
                          |P9_Pin|P10_Pin|P11_Pin|P12_Pin;
  GPIO_InitStruct.Mode = GPIO_MODE_OUTPUT_PP;
  GPIO_InitStruct.Pull = GPIO_NOPULL;
  GPIO_InitStruct.Speed = GPIO_SPEED_FREQ_LOW;
  HAL_GPIO_Init(GPIOA, &GPIO_InitStruct);

  /*Configure GPIO pin : PB0 */
  GPIO_InitStruct.Pin = GPIO_PIN_0;
  GPIO_InitStruct.Mode = GPIO_MODE_OUTPUT_PP;
  GPIO_InitStruct.Pull = GPIO_NOPULL;
  GPIO_InitStruct.Speed = GPIO_SPEED_FREQ_LOW;
  HAL_GPIO_Init(GPIOB, &GPIO_InitStruct);

}

void Error_Handler(void)
{
  __disable_irq();
  while (1)
  {
  }
}

/************************ (C) COPYRIGHT STMicroelectronics *****END OF FILE****/
